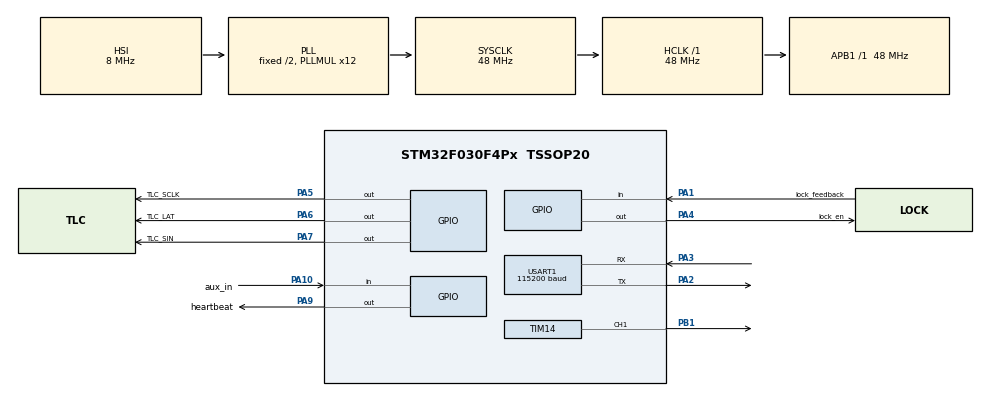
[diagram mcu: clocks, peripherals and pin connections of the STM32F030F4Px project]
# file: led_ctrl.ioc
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Dma.Request0=USART1_RX
Dma.USART1_RX.0.Direction=DMA_PERIPH_TO_MEMORY
Dma.USART1_RX.0.Instance=DMA1_Channel3
Dma.USART1_RX.0.MemDataAlignment=DMA_MDATAALIGN_BYTE
Dma.USART1_RX.0.MemInc=DMA_MINC_ENABLE
Dma.USART1_RX.0.Mode=DMA_NORMAL
Dma.USART1_RX.0.PeriphDataAlignment=DMA_PDATAALIGN_BYTE
Dma.USART1_RX.0.PeriphInc=DMA_PINC_DISABLE
Dma.USART1_RX.0.Priority=DMA_PRIORITY_LOW
IWDG.Prescaler=IWDG_PRESCALER_64
IWDG.Reload=1250
Mcu.Family=STM32F0
Mcu.Name=STM32F030F4Px
Mcu.Package=TSSOP20
NVIC.DMA1_Channel2_3_IRQn=true\:0\:0\:false\:false\:true\:false\:true\:true
NVIC.USART1_IRQn=true\:0\:0\:false\:false\:true\:true\:true\:true
PA1.GPIO_Label=lock_feedback
PA1.Signal=GPIO_Input
PA10.GPIO_Label=aux_in
PA10.Signal=GPIO_Input
PA13.Mode=Serial_Wire
PA13.Signal=SYS_SWDIO
PA14.Mode=Serial_Wire
PA14.Signal=SYS_SWCLK
PA2.Mode=Asynchronous
PA2.Signal=USART1_TX
PA3.Mode=Asynchronous
PA3.Signal=USART1_RX
PA4.GPIO_Label=lock_en
PA4.Signal=GPIO_Output
PA5.GPIO_Label=TLC_SCLK
PA5.GPIO_Speed=GPIO_SPEED_FREQ_HIGH
PA5.Signal=GPIO_Output
PA6.GPIO_Label=TLC_LAT
PA6.GPIO_Speed=GPIO_SPEED_FREQ_HIGH
PA6.Signal=GPIO_Output
PA7.GPIO_Label=TLC_SIN
PA7.GPIO_Speed=GPIO_SPEED_FREQ_HIGH
PA7.Signal=GPIO_Output
PA9.GPIO_Label=heartbeat
PA9.Signal=GPIO_Output
PB1.Signal=S_TIM14_CH1
ProjectManager.HeapSize=0x00
ProjectManager.StackSize=0x400
ProjectManager.TargetToolchain=STM32CubeIDE
RCC.AHBFreq_Value=48000000
RCC.APB1Freq_Value=48000000
RCC.APB1TimFreq_Value=48000000
RCC.HCLKFreq_Value=48000000
RCC.PLLMUL=RCC_PLL_MUL12
RCC.SYSCLKFreq_VALUE=48000000
RCC.SYSCLKSource=RCC_SYSCLKSOURCE_PLLCLK
SH.S_TIM14_CH1.0=TIM14_CH1,PWM Generation1 CH1
TIM14.Channel=TIM_CHANNEL_1
TIM14.Period=3
TIM14.Pulse=2
USART1.BaudRate=115200
USART1.VirtualMode-Asynchronous=VM_ASYNC
VP_IWDG_VS_IWDG.Mode=IWDG_Activate
VP_TIM14_VS_ClockSourceINT.Mode=Enable_Timer
board=custom

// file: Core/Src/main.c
/* USER CODE BEGIN Header */
/**
  ******************************************************************************
  * @file           : main.c
  * @brief          : Main program body
  ******************************************************************************
  * @attention
  *
  * Copyright (c) 2026 STMicroelectronics.
  * All rights reserved.
  *
  * This software is licensed under terms that can be found in the LICENSE file
  * in the root directory of this software component.
  * If no LICENSE file comes with this software, it is provided AS-IS.
  *
  ******************************************************************************
  */
/* USER CODE END Header */
#include "main.h"
#include "dma.h"
#include "iwdg.h"
#include "tim.h"
#include "usart.h"
#include "gpio.h"

/* USER CODE BEGIN Includes */
#include "board_config.h"
#include "bsp_uart.h"
#include "app.h"

/* USER CODE END Includes */

void SystemClock_Config(void);

int main(void)
{

  /* MCU Configuration--------------------------------------------------------*/

  /* Reset of all peripherals, Initializes the Flash interface and the Systick. */
  HAL_Init();

  /* Configure the system clock */
  SystemClock_Config();

  /* USER CODE BEGIN SysInit */

  /* The IWDG cannot be stopped once started, and it keeps counting while SWD
   * holds the core at a breakpoint, so freeze it before it ever runs or every
   * single-step session gets cut short by a 2 s reset.
   * On F0 the DBGMCU sits on APB2: without enabling its clock first, the write
   * to APB1FZ below is a silent no-op - no error, no warning. */
  __HAL_RCC_DBGMCU_CLK_ENABLE();
  __HAL_DBGMCU_FREEZE_IWDG();

  /* USER CODE END SysInit */

  /* Initialize all configured peripherals */
  MX_GPIO_Init();
  MX_DMA_Init();
  MX_TIM14_Init();
  MX_USART1_UART_Init();
  MX_IWDG_Init();
  /* USER CODE BEGIN 2 */
  App_Init();

  /* USER CODE END 2 */

  /* Infinite loop */
  while (1)
  {

    /* USER CODE BEGIN 3 */
    /* Kick the watchdog. MX_IWDG_Init() has already started it, so without
     * this line the board resets every 2 s. */
    HAL_IWDG_Refresh(&hiwdg);
    App_Tick(HAL_GetTick());
  }
  /* USER CODE END 3 */
}

void SystemClock_Config(void)
{
  RCC_OscInitTypeDef RCC_OscInitStruct = {0};
  RCC_ClkInitTypeDef RCC_ClkInitStruct = {0};
  RCC_PeriphCLKInitTypeDef PeriphClkInit = {0};

  /** Initializes the RCC Oscillators according to the specified parameters
  * in the RCC_OscInitTypeDef structure.
  */
  RCC_OscInitStruct.OscillatorType = RCC_OSCILLATORTYPE_HSI|RCC_OSCILLATORTYPE_LSI;
  RCC_OscInitStruct.HSIState = RCC_HSI_ON;
  RCC_OscInitStruct.HSICalibrationValue = RCC_HSICALIBRATION_DEFAULT;
  RCC_OscInitStruct.LSIState = RCC_LSI_ON;
  RCC_OscInitStruct.PLL.PLLState = RCC_PLL_ON;
  RCC_OscInitStruct.PLL.PLLSource = RCC_PLLSOURCE_HSI;
  RCC_OscInitStruct.PLL.PLLMUL = RCC_PLL_MUL12;
  RCC_OscInitStruct.PLL.PREDIV = RCC_PREDIV_DIV1;
  if (HAL_RCC_OscConfig(&RCC_OscInitStruct) != HAL_OK)
  {
    Error_Handler();
  }

  /** Initializes the CPU, AHB and APB buses clocks
  */
  RCC_ClkInitStruct.ClockType = RCC_CLOCKTYPE_HCLK|RCC_CLOCKTYPE_SYSCLK
                              |RCC_CLOCKTYPE_PCLK1;
  RCC_ClkInitStruct.SYSCLKSource = RCC_SYSCLKSOURCE_PLLCLK;
  RCC_ClkInitStruct.AHBCLKDivider = RCC_SYSCLK_DIV1;
  RCC_ClkInitStruct.APB1CLKDivider = RCC_HCLK_DIV1;

  if (HAL_RCC_ClockConfig(&RCC_ClkInitStruct, FLASH_LATENCY_1) != HAL_OK)
  {
    Error_Handler();
  }
  PeriphClkInit.PeriphClockSelection = RCC_PERIPHCLK_USART1;
  PeriphClkInit.Usart1ClockSelection = RCC_USART1CLKSOURCE_PCLK1;
  if (HAL_RCCEx_PeriphCLKConfig(&PeriphClkInit) != HAL_OK)
  {
    Error_Handler();
  }
}

void Error_Handler(void)
{
  __disable_irq();
  while (1)
  {
  }
}
